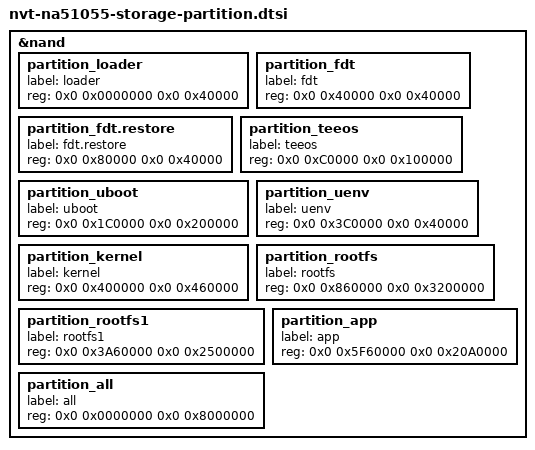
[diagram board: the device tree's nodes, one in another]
/*
 * Novatek Ltd. NA51055 BSP part of dts
 *
 * Cortex-A9
 *
 */

&nand {
	partition_loader {      label = "loader";       reg = <0x0 0x0000000 0x0 0x40000>; }; /* Fixed */
	partition_fdt {	        label = "fdt";	        reg = <0x0 0x40000   0x0 0x40000>; }; /* Fixed */
	partition_fdt.restore {	label = "fdt.restore";	reg = <0x0 0x80000   0x0 0x40000>; }; /* Fixed */
	partition_teeos {       label = "teeos";        reg = <0x0 0xC0000   0x0 0x100000>; };
	partition_uboot {       label = "uboot";        reg = <0x0 0x1C0000  0x0 0x200000>; };
	partition_uenv {        label = "uenv";         reg = <0x0 0x3C0000  0x0 0x40000>; };
	partition_kernel {      label = "kernel";       reg = <0x0 0x400000  0x0 0x460000>; };
	partition_rootfs {      label = "rootfs";       reg = <0x0 0x860000  0x0 0x3200000>; };
	partition_rootfs1 {     label = "rootfs1";      reg = <0x0 0x3A60000 0x0 0x2500000>; };
	partition_app {  	label = "app";          reg = <0x0 0x5F60000 0x0 0x20A0000>; }; /* app size depneds on hdal/samples/vendor_cfg/Makeile: ROOTFS_UBI_MAX_LEB_COUNT */
	partition_all {  	label = "all";          reg = <0x0 0x0000000 0x0 0x8000000>; };
};
